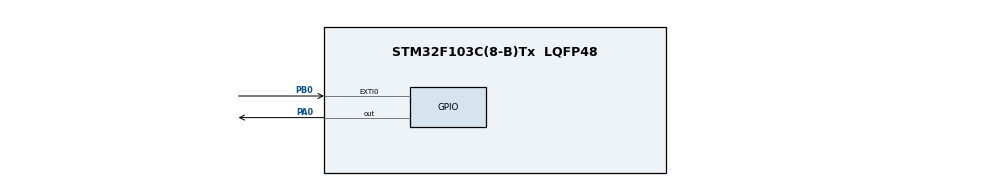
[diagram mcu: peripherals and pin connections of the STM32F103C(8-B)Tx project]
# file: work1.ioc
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Mcu.Family=STM32F1
Mcu.Name=STM32F103C(8-B)Tx
Mcu.Package=LQFP48
NVIC.EXTI0_IRQn=true\:0\:0\:false\:false\:true\:true\:true\:true
NVIC.PriorityGroup=NVIC_PRIORITYGROUP_4
PA0-WKUP.Signal=GPIO_Output
PA13.Mode=Serial_Wire
PA13.Signal=SYS_JTMS-SWDIO
PA14.Mode=Serial_Wire
PA14.Signal=SYS_JTCK-SWCLK
PB0.GPIO_PuPd=GPIO_PULLUP
PB0.Signal=GPXTI0
PD0-OSC_IN.Mode=HSE-External-Oscillator
PD0-OSC_IN.Signal=RCC_OSC_IN
PD1-OSC_OUT.Mode=HSE-External-Oscillator
PD1-OSC_OUT.Signal=RCC_OSC_OUT
ProjectManager.HeapSize=0x200
ProjectManager.StackSize=0x400
ProjectManager.TargetToolchain=MDK-ARM V5.32
RCC.APB1Freq_Value=8000000
RCC.APB2Freq_Value=8000000
board=custom

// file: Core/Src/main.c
/* USER CODE BEGIN Header */
/**
  ******************************************************************************
  * @file           : main.c
  * @brief          : Main program body
  ******************************************************************************
  * @attention
  *
  * Copyright (c) 2026 STMicroelectronics.
  * All rights reserved.
  *
  * This software is licensed under terms that can be found in the LICENSE file
  * in the root directory of this software component.
  * If no LICENSE file comes with this software, it is provided AS-IS.
  *
  ******************************************************************************
  */
/* USER CODE END Header */
#include "main.h"
#include "gpio.h"

/* USER CODE BEGIN PV */
static uint32_t s_last_tick=0;
/* USER CODE END PV */

void SystemClock_Config(void);

int main(void)
{

  /* USER CODE BEGIN 1 */
GPIO_InitTypeDef PC13_Init = {0};
  /* USER CODE END 1 */

  /* MCU Configuration--------------------------------------------------------*/

  /* Reset of all peripherals, Initializes the Flash interface and the Systick. */
  HAL_Init();

  /* Configure the system clock */
  SystemClock_Config();

  /* Initialize all configured peripherals */
  MX_GPIO_Init();
  /* USER CODE BEGIN 2 */
	s_last_tick=HAL_GetTick();
  /* USER CODE END 2 */

  /* Infinite loop */
  while (1)
  {

    /* USER CODE BEGIN 3 */
		if ((HAL_GetTick()-s_last_tick)>=500U)
		{
			s_last_tick=HAL_GetTick();
			HAL_GPIO_TogglePin(GPIOA,GPIO_PIN_0);
		}
  }
  /* USER CODE END 3 */
}

void SystemClock_Config(void)
{
  RCC_OscInitTypeDef RCC_OscInitStruct = {0};
  RCC_ClkInitTypeDef RCC_ClkInitStruct = {0};

  /** Initializes the RCC Oscillators according to the specified parameters
  * in the RCC_OscInitTypeDef structure.
  */
  RCC_OscInitStruct.OscillatorType = RCC_OSCILLATORTYPE_HSI;
  RCC_OscInitStruct.HSIState = RCC_HSI_ON;
  RCC_OscInitStruct.HSICalibrationValue = RCC_HSICALIBRATION_DEFAULT;
  RCC_OscInitStruct.PLL.PLLState = RCC_PLL_NONE;
  if (HAL_RCC_OscConfig(&RCC_OscInitStruct) != HAL_OK)
  {
    Error_Handler();
  }

  /** Initializes the CPU, AHB and APB buses clocks
  */
  RCC_ClkInitStruct.ClockType = RCC_CLOCKTYPE_HCLK|RCC_CLOCKTYPE_SYSCLK
                              |RCC_CLOCKTYPE_PCLK1|RCC_CLOCKTYPE_PCLK2;
  RCC_ClkInitStruct.SYSCLKSource = RCC_SYSCLKSOURCE_HSI;
  RCC_ClkInitStruct.AHBCLKDivider = RCC_SYSCLK_DIV1;
  RCC_ClkInitStruct.APB1CLKDivider = RCC_HCLK_DIV1;
  RCC_ClkInitStruct.APB2CLKDivider = RCC_HCLK_DIV1;

  if (HAL_RCC_ClockConfig(&RCC_ClkInitStruct, FLASH_LATENCY_0) != HAL_OK)
  {
    Error_Handler();
  }
}

void Error_Handler(void)
{
  __disable_irq();
  while (1)
  {
  }
}
